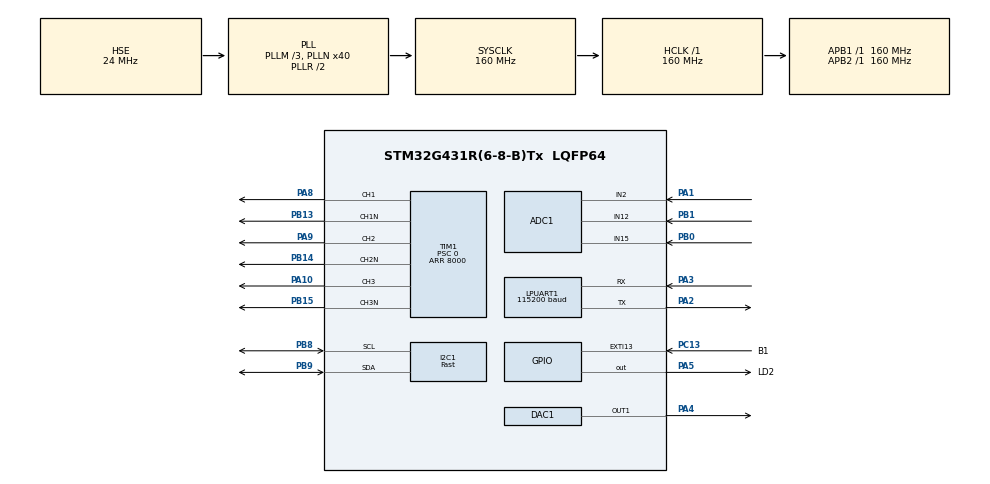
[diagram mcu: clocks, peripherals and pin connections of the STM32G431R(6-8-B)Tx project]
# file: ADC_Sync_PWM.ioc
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ADC1.Channel-4\#ChannelRegularConversion=ADC_CHANNEL_TEMPSENSOR_ADC1
ADC1.EOCSelection=ADC_EOC_SEQ_CONV
ADC1.EnableInjectedConversion=ENABLE
ADC1.ExternalTrigConv=ADC_EXTERNALTRIG_T6_TRGO
ADC1.ExternalTrigInjecConv=ADC_EXTERNALTRIGINJEC_T1_TRGO2
ADC1.InjNumberOfConversion=3
ADC1.InjectedChannel-5\#ChannelInjectedConversion=ADC_CHANNEL_2
ADC1.InjectedChannel-6\#ChannelInjectedConversion=ADC_CHANNEL_12
ADC1.InjectedChannel-7\#ChannelInjectedConversion=ADC_CHANNEL_15
ADC1.InjectedOffsetNumber-5\#ChannelInjectedConversion=ADC_OFFSET_NONE
ADC1.InjectedOffsetNumber-6\#ChannelInjectedConversion=ADC_OFFSET_NONE
ADC1.InjectedOffsetNumber-7\#ChannelInjectedConversion=ADC_OFFSET_NONE
ADC1.InjectedRank-5\#ChannelInjectedConversion=1
ADC1.InjectedRank-6\#ChannelInjectedConversion=2
ADC1.InjectedRank-7\#ChannelInjectedConversion=3
ADC1.InjectedSamplingTime-5\#ChannelInjectedConversion=ADC_SAMPLETIME_24CYCLES_5
ADC1.InjectedSamplingTime-6\#ChannelInjectedConversion=ADC_SAMPLETIME_24CYCLES_5
ADC1.InjectedSamplingTime-7\#ChannelInjectedConversion=ADC_SAMPLETIME_24CYCLES_5
ADC1.NbrOfConversionFlag=1
ADC1.OffsetNumber-4\#ChannelRegularConversion=ADC_OFFSET_NONE
ADC1.Rank-4\#ChannelRegularConversion=1
ADC1.SamplingTime-4\#ChannelRegularConversion=ADC_SAMPLETIME_247CYCLES_5
ADC1.master=1
Dma.LPUART1_TX.0.Direction=DMA_MEMORY_TO_PERIPH
Dma.LPUART1_TX.0.EventEnable=DISABLE
Dma.LPUART1_TX.0.Instance=DMA1_Channel2
Dma.LPUART1_TX.0.MemDataAlignment=DMA_MDATAALIGN_BYTE
Dma.LPUART1_TX.0.MemInc=DMA_MINC_ENABLE
Dma.LPUART1_TX.0.Mode=DMA_NORMAL
Dma.LPUART1_TX.0.PeriphDataAlignment=DMA_PDATAALIGN_BYTE
Dma.LPUART1_TX.0.PeriphInc=DMA_PINC_DISABLE
Dma.LPUART1_TX.0.Polarity=HAL_DMAMUX_REQ_GEN_RISING
Dma.LPUART1_TX.0.Priority=DMA_PRIORITY_LOW
Dma.LPUART1_TX.0.RequestNumber=1
Dma.LPUART1_TX.0.SignalID=NONE
Dma.LPUART1_TX.0.SyncEnable=DISABLE
Dma.LPUART1_TX.0.SyncPolarity=HAL_DMAMUX_SYNC_NO_EVENT
Dma.LPUART1_TX.0.SyncRequestNumber=1
Dma.LPUART1_TX.0.SyncSignalID=NONE
Dma.Request0=LPUART1_TX
I2C1.I2C_Speed_Mode=I2C_Fast
I2C1.Timing=0x10F32A82
LPUART1.BaudRate=115200
Mcu.Family=STM32G4
Mcu.Name=STM32G431R(6-8-B)Tx
Mcu.Package=LQFP64
NVIC.ADC1_2_IRQn=true\:0\:0\:false\:false\:true\:true\:true\:true
NVIC.DMA1_Channel2_IRQn=true\:2\:0\:true\:false\:true\:false\:true\:true
NVIC.EXTI15_10_IRQn=true\:4\:0\:true\:false\:true\:true\:true\:true
NVIC.LPUART1_IRQn=true\:3\:0\:true\:false\:true\:true\:true\:true
NVIC.PriorityGroup=NVIC_PRIORITYGROUP_4
NVIC.TIM6_DAC_IRQn=true\:1\:0\:true\:false\:true\:true\:true\:true
PA1.Mode=IN2-Single-Ended
PA1.Signal=ADC1_IN2
PA10.Signal=S_TIM1_CH3
PA13.Mode=Serial_Wire
PA13.Signal=SYS_JTMS-SWDIO
PA14.Mode=Serial_Wire
PA14.Signal=SYS_JTCK-SWCLK
PA2.Mode=Asynchronous
PA2.Signal=LPUART1_TX
PA3.Mode=Asynchronous
PA3.Signal=LPUART1_RX
PA4.Signal=COMP_DAC11_group
PA5.GPIO_Label=LD2
PA5.Signal=GPIO_Output
PA8.Signal=S_TIM1_CH1
PA9.Signal=S_TIM1_CH2
PB0.Mode=IN15-Single-Ended
PB0.Signal=ADC1_IN15
PB1.Mode=IN12-Single-Ended
PB1.Signal=ADC1_IN12
PB13.Mode=PWM Generation1 CH1 CH1N
PB13.Signal=TIM1_CH1N
PB14.Mode=PWM Generation2 CH2 CH2N
PB14.Signal=TIM1_CH2N
PB15.Mode=PWM Generation3 CH3 CH3N
PB15.Signal=TIM1_CH3N
PB8-BOOT0.Mode=I2C
PB8-BOOT0.Signal=I2C1_SCL
PB9.Mode=I2C
PB9.Signal=I2C1_SDA
PC13.GPIO_Label=B1
PC13.GPIO_ModeDefaultEXTI=GPIO_MODE_IT_RISING
PC13.Signal=GPXTI13
PF0-OSC_IN.Mode=HSE-External-Oscillator
PF0-OSC_IN.Signal=RCC_OSC_IN
PF1-OSC_OUT.Mode=HSE-External-Oscillator
PF1-OSC_OUT.Signal=RCC_OSC_OUT
ProjectManager.HeapSize=0x200
ProjectManager.StackSize=0x400
ProjectManager.TargetToolchain=CMake
RCC.ADC12Freq_Value=160000000
RCC.AHBFreq_Value=160000000
RCC.APB1Freq_Value=160000000
RCC.APB1TimFreq_Value=160000000
RCC.APB2Freq_Value=160000000
RCC.APB2TimFreq_Value=160000000
RCC.CortexFreq_Value=160000000
RCC.EXTERNAL_CLOCK_VALUE=12288000
RCC.HCLKFreq_Value=160000000
RCC.HSE_VALUE=24000000
RCC.HSI48_VALUE=48000000
RCC.HSI_VALUE=16000000
RCC.LSE_VALUE=32768
RCC.PLLM=RCC_PLLM_DIV3
RCC.PLLN=40
RCC.PLLSourceVirtual=RCC_PLLSOURCE_HSE
RCC.SYSCLKFreq_VALUE=160000000
RCC.SYSCLKSource=RCC_SYSCLKSOURCE_PLLCLK
RCC.USBFreq_Value=160000000
RCC.VCOOutputFreq_Value=320000000
SH.COMP_DAC11_group.0=DAC1_OUT1,DAC_OUT1
SH.S_TIM1_CH1.0=TIM1_CH1,PWM Generation1 CH1 CH1N
SH.S_TIM1_CH2.0=TIM1_CH2,PWM Generation2 CH2 CH2N
SH.S_TIM1_CH3.0=TIM1_CH3,PWM Generation3 CH3 CH3N
TIM1.AutoReloadPreload=TIM_AUTORELOAD_PRELOAD_ENABLE
TIM1.AutomaticOutput=TIM_AUTOMATICOUTPUT_DISABLE
TIM1.BreakFilter=1
TIM1.Channel-PWM\ Generation1\ CH1\ CH1N=TIM_CHANNEL_1
TIM1.Channel-PWM\ Generation2\ CH2\ CH2N=TIM_CHANNEL_2
TIM1.Channel-PWM\ Generation3\ CH3\ CH3N=TIM_CHANNEL_3
TIM1.Channel-PWM\ Generation4\ No\ Output=TIM_CHANNEL_4
TIM1.ClockDivision=TIM_CLOCKDIVISION_DIV1
TIM1.CounterMode=TIM_COUNTERMODE_CENTERALIGNED1
TIM1.DeadTime=32
TIM1.DeadTimePreload=ENABLE
TIM1.PeriodNoDither=8000
TIM1.Prescaler=0
TIM1.PulseNoDither_1=0
TIM1.PulseNoDither_2=0
TIM1.PulseNoDither_3=0
TIM1.PulseNoDither_4=4000
TIM1.RepetitionCounter=0
TIM1.TIM_MasterOutputTrigger=TIM_TRGO_RESET
TIM1.TIM_MasterOutputTrigger2=TIM_TRGO2_OC4REF
TIM1.TIM_MasterSlaveMode=TIM_MASTERSLAVEMODE_DISABLE
TIM6.PeriodNoDither=1999
TIM6.Prescaler=159
TIM6.TIM_MasterOutputTrigger=TIM_TRGO_UPDATE
VP_ADC1_TempSens_Input.Mode=IN-TempSens
VP_SYS_VS_DBSignals.Mode=DisableDeadBatterySignals
VP_TIM1_VS_ClockSourceINT.Mode=Internal
VP_TIM1_VS_no_output4.Mode=PWM Generation4 No Output
VP_TIM6_VS_ClockSourceINT.Mode=Enable_Timer
board=NUCLEO-G431RB

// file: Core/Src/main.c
/* USER CODE BEGIN Header */
/**
  ******************************************************************************
  * @file           : main.c
  * @brief          : Main program body
  ******************************************************************************
  * @attention
  *
  * Copyright (c) 2026 STMicroelectronics.
  * All rights reserved.
  *
  * This software is licensed under terms that can be found in the LICENSE file
  * in the root directory of this software component.
  * If no LICENSE file comes with this software, it is provided AS-IS.
  *
  ******************************************************************************
  */
/* USER CODE END Header */
#include "main.h"
#include "adc.h"
#include "dac.h"
#include "dma.h"
#include "i2c.h"
#include "usart.h"
#include "tim.h"
#include "gpio.h"

/* USER CODE BEGIN Includes */
#include "app_control.h"
#include "app_display.h"
/* USER CODE END Includes */

/* USER CODE BEGIN PD */
#define DISP_REFRESH_PERIOD_MS   100U   /* OLED 主循环周期刷新间隔：100 ms（10 Hz） */
/* USER CODE END PD */

/* USER CODE BEGIN PV */
static uint32_t disp_last_tick = 0U;   /* OLED 刷新上次执行时间戳（HAL_GetTick） */
/* USER CODE END PV */

void SystemClock_Config(void);

int main(void)
{

  /* MCU Configuration--------------------------------------------------------*/

  /* Reset of all peripherals, Initializes the Flash interface and the Systick. */
  HAL_Init();

  /* Configure the system clock */
  SystemClock_Config();

  /* Initialize all configured peripherals */
  MX_GPIO_Init();
  MX_DMA_Init();
  MX_TIM1_Init();
  MX_ADC1_Init();
  MX_LPUART1_UART_Init();
  MX_DAC1_Init();
  MX_TIM6_Init();
  MX_I2C1_Init();
  /* USER CODE BEGIN 2 */
  APP_Control_Init();
  /* OLED 显示（TS01 基础初始化 + TS02 首帧真实组屏刷新）：
   * 在 I2C1 与控制模块初始化后初始化 OLED，并立即按当前运行数据组屏刷新一次，
   * 使启动后屏幕即显示真实状态（STOP：STATE/TEMP/DAC: OFF），不在启动阶段显示 TS01 固定测试内容。 */
  DISP_Init();
  DISP_Refresh();
  /* USER CODE END 2 */

  /* Infinite loop */
  while (1)
  {

    /* USER CODE BEGIN 3 */
    /* OLED 周期刷新（TS02）：HAL_GetTick 守时，100 ms 一次；I2C 传输仅在主循环执行，不进 ISR。
     * 时间差比较使主循环不阻塞，可被实时中断正常抢占。 */
    uint32_t now = HAL_GetTick();
    if ((now - disp_last_tick) >= DISP_REFRESH_PERIOD_MS) {
      disp_last_tick = now;
      DISP_Refresh();
    }
  }
  /* USER CODE END 3 */
}

void SystemClock_Config(void)
{
  RCC_OscInitTypeDef RCC_OscInitStruct = {0};
  RCC_ClkInitTypeDef RCC_ClkInitStruct = {0};

  /** Configure the main internal regulator output voltage
  */
  HAL_PWREx_ControlVoltageScaling(PWR_REGULATOR_VOLTAGE_SCALE1_BOOST);

  /** Initializes the RCC Oscillators according to the specified parameters
  * in the RCC_OscInitTypeDef structure.
  */
  RCC_OscInitStruct.OscillatorType = RCC_OSCILLATORTYPE_HSE;
  RCC_OscInitStruct.HSEState = RCC_HSE_ON;
  RCC_OscInitStruct.PLL.PLLState = RCC_PLL_ON;
  RCC_OscInitStruct.PLL.PLLSource = RCC_PLLSOURCE_HSE;
  RCC_OscInitStruct.PLL.PLLM = RCC_PLLM_DIV3;
  RCC_OscInitStruct.PLL.PLLN = 40;
  RCC_OscInitStruct.PLL.PLLP = RCC_PLLP_DIV2;
  RCC_OscInitStruct.PLL.PLLQ = RCC_PLLQ_DIV2;
  RCC_OscInitStruct.PLL.PLLR = RCC_PLLR_DIV2;
  if (HAL_RCC_OscConfig(&RCC_OscInitStruct) != HAL_OK)
  {
    Error_Handler();
  }

  /** Initializes the CPU, AHB and APB buses clocks
  */
  RCC_ClkInitStruct.ClockType = RCC_CLOCKTYPE_HCLK|RCC_CLOCKTYPE_SYSCLK
                              |RCC_CLOCKTYPE_PCLK1|RCC_CLOCKTYPE_PCLK2;
  RCC_ClkInitStruct.SYSCLKSource = RCC_SYSCLKSOURCE_PLLCLK;
  RCC_ClkInitStruct.AHBCLKDivider = RCC_SYSCLK_DIV1;
  RCC_ClkInitStruct.APB1CLKDivider = RCC_HCLK_DIV1;
  RCC_ClkInitStruct.APB2CLKDivider = RCC_HCLK_DIV1;

  if (HAL_RCC_ClockConfig(&RCC_ClkInitStruct, FLASH_LATENCY_4) != HAL_OK)
  {
    Error_Handler();
  }
}

void Error_Handler(void)
{
  __disable_irq();
  while (1)
  {
  }
}
